# S32K342_M7 register map
Vendor: NXP Semiconductors; File version: 1.5
CPU: CM7 r0p1, little endian, MPU, FPU, VTOR, 4 interrupt priority bits
Registers are 32-bit, read-write, reset 0x0 unless marked. A register's access mark holds for its fields unless they carry their own. Offsets are from the block's base; [hi:lo] are bit positions; {n}, {i} and the like mark numbered series.

## EIM
Base 0x40258000
0x00 EIMCR — Error Injection Module Configuration Register
  [0] GEIEN — Global Error Injection Enable
    0=DISABLE (Disabled); 1=ENABLE (Enabled)
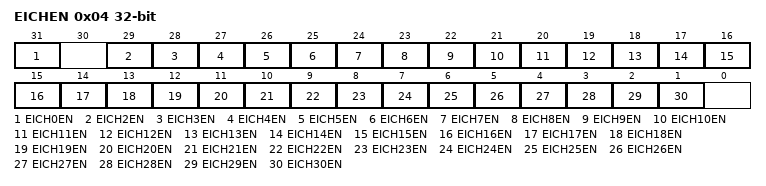
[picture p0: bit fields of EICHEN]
0x04 EICHEN — Error Injection Channel Enable register
  [31] EICH0EN — Error Injection Channel 0 Enable
    0=DISABLE (Error injection is disabled on Error Injection Channel 0); 1=ENABLE (Error injection is enabled on Error Injection Channel 0)
  [31-n] EICH{n}EN (n=2..30) — Error Injection Channel {n} Enable
    0=DISABLE (Error injection is disabled on Error Injection Channel {n}); 1=ENABLE (Error injection is enabled on Error Injection Channel {n})
0x100 EICHD0_WORD0 — Error Injection Channel Descriptor 0, Word0
  [31:24] CHKBIT_MASK — Checkbit Mask
0x104 EICHD0_WORD1 — Error Injection Channel Descriptor 0, Word1
  [31:0] B0_3DATA_MASK — Data Mask Bytes 0-3
0x108 EICHD0_WORD2 — Error Injection Channel Descriptor 0, Word2
  [31:0] B4_7DATA_MASK — Data Mask Bytes 4-7
0x180 EICHD2_WORD0 — Error Injection Channel Descriptor 2, Word0
  [31:24] CHKBIT_MASK — Checkbit Mask
0x184 EICHD2_WORD1 — Error Injection Channel Descriptor 2, Word1
  [31:0] B0_3DATA_MASK — Data Mask Bytes 0-3
{0x108+0x40*i} EICHD{i}_WORD2 (i=2..13) — Error Injection Channel Descriptor {i}, Word2
  [31:0] B4_7DATA_MASK — Data Mask Bytes 4-7
0x1C0 EICHD3_WORD0 — Error Injection Channel Descriptor 3, Word0
  [31:18] CHKBIT_MASK — Checkbit Mask
0x1C4 EICHD3_WORD1 — Error Injection Channel Descriptor 3, Word1
  [11:0] B0_3DATA_MASK — Data Mask Bytes 0-3
0x200 EICHD4_WORD0 — Error Injection Channel Descriptor 4, Word0
  [31:16] CHKBIT_MASK — Checkbit Mask
0x204 EICHD4_WORD1 — Error Injection Channel Descriptor 4, Word1
  [31:0] B0_3DATA_MASK — Data Mask Bytes 0-3
{0x10C+0x40*i} EICHD{i}_WORD3 (i=4..7) — Error Injection Channel Descriptor {i}, Word3
  [31:0] B8_11DATA_MASK — Data Mask Bytes 8-11
{0x110+0x40*i} EICHD{i}_WORD4 (i=4..7) — Error Injection Channel Descriptor {i}, Word4
  [31:0] B12_15DATA_MASK — Data Mask Bytes 12-15
{0x100+0x40*i} EICHD{i}_WORD0 (i=5..7) — Error Injection Channel Descriptor {i}, Word0
  [31:4] CHKBIT_MASK — Checkbit Mask
0x244 EICHD5_WORD1 — Error Injection Channel Descriptor 5, Word1
  [7:0] B0_3DATA_MASK — Data Mask Bytes 0-3
0x284 EICHD6_WORD1 — Error Injection Channel Descriptor 6, Word1
  [31:0] B0_3DATA_MASK — Data Mask Bytes 0-3
0x2C4 EICHD7_WORD1 — Error Injection Channel Descriptor 7, Word1
  [31:0] B0_3DATA_MASK — Data Mask Bytes 0-3
0x300 EICHD8_WORD0 — Error Injection Channel Descriptor 8, Word0
  [31:18] CHKBIT_MASK — Checkbit Mask
0x304 EICHD8_WORD1 — Error Injection Channel Descriptor 8, Word1
  [11:0] B0_3DATA_MASK — Data Mask Bytes 0-3
0x340 EICHD9_WORD0 — Error Injection Channel Descriptor 9, Word0
  [31:16] CHKBIT_MASK — Checkbit Mask
0x344 EICHD9_WORD1 — Error Injection Channel Descriptor 9, Word1
  [31:0] B0_3DATA_MASK — Data Mask Bytes 0-3
{0x10C+0x40*i} EICHD{i}_WORD3 (i=9..12) — Error Injection Channel Descriptor {i}, Word3
  [31:0] B8_11DATA_MASK — Data Mask Bytes 8-11
{0x110+0x40*i} EICHD{i}_WORD4 (i=9..12) — Error Injection Channel Descriptor {i}, Word4
  [31:0] B12_15DATA_MASK — Data Mask Bytes 12-15
{0x100+0x40*i} EICHD{i}_WORD0 (i=10..12) — Error Injection Channel Descriptor {i}, Word0
  [31:4] CHKBIT_MASK — Checkbit Mask
0x384 EICHD10_WORD1 — Error Injection Channel Descriptor 10, Word1
  [7:0] B0_3DATA_MASK — Data Mask Bytes 0-3
{0x104+0x40*i} EICHD{i}_WORD1 (i=11..18) — Error Injection Channel Descriptor {i}, Word1
  [31:0] B0_3DATA_MASK — Data Mask Bytes 0-3
{0x100+0x40*i} EICHD{i}_WORD0 (i=13..18) — Error Injection Channel Descriptor {i}, Word0
  [31:24] CHKBIT_MASK — Checkbit Mask
0x508 EICHD16_WORD2 — Error Injection Channel Descriptor 16, Word2
  [31:0] B4_7DATA_MASK — Data Mask Bytes 4-7
{0x104+0x40*i} EICHD{i}_WORD1 (i=19..26) — Error Injection Channel Descriptor {i}, Word1
  [27:0] B0_3DATA_MASK — Data Mask Bytes 0-3
{0x108+0x40*i} EICHD{i}_WORD2 (i=19..26) — Error Injection Channel Descriptor {i}, Word2
  [31:0] B4_7DATA_MASK — Data Mask Bytes 4-7
0x5CC EICHD19_WORD3 — Error Injection Channel Descriptor 19, Word3
  [31:0] B8_11DATA_MASK — Data Mask Bytes 8-11
0x5D0 EICHD19_WORD4 — Error Injection Channel Descriptor 19, Word4
  [31:0] B12_15DATA_MASK — Data Mask Bytes 12-15
0x5D4 EICHD19_WORD5 — Error Injection Channel Descriptor 19, Word5
  [31:0] B16_19DATA_MASK — Data Mask Bytes 16-19
0x5D8 EICHD19_WORD6 — Error Injection Channel Descriptor 19, Word6
  [31:0] B20_23DATA_MASK — Data Mask Bytes 20-23
0x60C EICHD20_WORD3 — Error Injection Channel Descriptor 20, Word3
  [31:0] B8_11DATA_MASK — Data Mask Bytes 8-11
0x610 EICHD20_WORD4 — Error Injection Channel Descriptor 20, Word4
  [31:0] B12_15DATA_MASK — Data Mask Bytes 12-15
0x614 EICHD20_WORD5 — Error Injection Channel Descriptor 20, Word5
  [31:0] B16_19DATA_MASK — Data Mask Bytes 16-19
0x618 EICHD20_WORD6 — Error Injection Channel Descriptor 20, Word6
  [31:0] B20_23DATA_MASK — Data Mask Bytes 20-23
0x7C4 EICHD27_WORD1 — Error Injection Channel Descriptor 27, Word1
  [29:0] B0_3DATA_MASK — Data Mask Bytes 0-3
0x804 EICHD28_WORD1 — Error Injection Channel Descriptor 28, Word1
  [27:0] B0_3DATA_MASK — Data Mask Bytes 0-3
0x844 EICHD29_WORD1 — Error Injection Channel Descriptor 29, Word1
  [17:0] B0_3DATA_MASK — Data Mask Bytes 0-3
0x884 EICHD30_WORD1 — Error Injection Channel Descriptor 30, Word1
  [17:0] B0_3DATA_MASK — Data Mask Bytes 0-3
